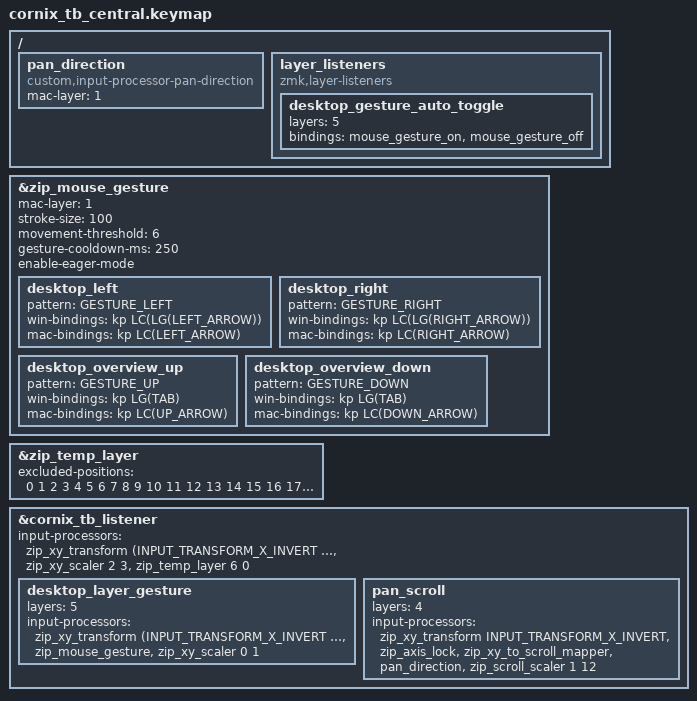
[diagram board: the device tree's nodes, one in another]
/* SPDX-License-Identifier: MIT */
/* The TB-specific editable map is the source of its key layers. */
#include "../../../config/Cornix_tb.keymap"
#include <mouse-gesture.dtsi>

&zip_mouse_gesture {
    mac-layer = <1>;
    stroke-size = <100>;
    movement-threshold = <6>;
    gesture-cooldown-ms = <250>;
    enable-eager-mode;

    desktop_left {
        pattern = <GESTURE_LEFT>;
        win-bindings = <&kp LC(LG(LEFT_ARROW))>;
        mac-bindings = <&kp LC(LEFT_ARROW)>;
    };

    desktop_right {
        pattern = <GESTURE_RIGHT>;
        win-bindings = <&kp LC(LG(RIGHT_ARROW))>;
        mac-bindings = <&kp LC(RIGHT_ARROW)>;
    };

    desktop_overview_up {
        pattern = <GESTURE_UP>;
        win-bindings = <&kp LG(TAB)>;
        mac-bindings = <&kp LC(UP_ARROW)>;
    };

    desktop_overview_down {
        pattern = <GESTURE_DOWN>;
        win-bindings = <&kp LG(TAB)>;
        mac-bindings = <&kp LC(DOWN_ARROW)>;
    };
};

&zip_temp_layer {
    /* All positions except LANG2 (42) and LANG1 (45) keep AML active. */
    excluded-positions = <0 1 2 3 4 5 6 7 8 9 10 11 12 13 14 15 16 17 18 19 20 21 22 23 24 25 26 27 28 29 30 31 32 33 34 35 36 37 38 39 40 41 43 44 46 47 48>;
};

&cornix_tb_listener {
    /* Provisional orientation: adjust for the final sensor mounting. */
    input-processors = <&zip_xy_transform
        (INPUT_TRANSFORM_X_INVERT | INPUT_TRANSFORM_Y_INVERT)>,
        <&zip_xy_scaler 2 3>, <&zip_temp_layer 6 0>;

    /* Layer 5 uses desktop gestures, with no pointer output. */
    desktop_layer_gesture {
        layers = <5>;
        input-processors = <&zip_xy_transform
            (INPUT_TRANSFORM_X_INVERT | INPUT_TRANSFORM_Y_INVERT)>,
            <&zip_mouse_gesture>, <&zip_xy_scaler 0 1>;
    };

    pan_scroll {
        layers = <4>;
        input-processors = <&zip_xy_transform INPUT_TRANSFORM_X_INVERT>,
            <&zip_axis_lock>, <&zip_xy_to_scroll_mapper>,
            <&pan_direction>, <&zip_scroll_scaler 1 12>;
    };
};

/ {
    pan_direction: pan_direction {
        compatible = "custom,input-processor-pan-direction";
        #input-processor-cells = <0>;
        mac-layer = <1>;
    };

    layer_listeners {
        compatible = "zmk,layer-listeners";
        desktop_gesture_auto_toggle {
            layers = <5>;
            bindings = <&mouse_gesture_on &mouse_gesture_off>;
        };
    };
};
